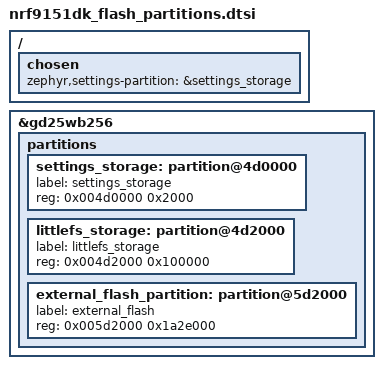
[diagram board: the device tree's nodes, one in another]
/*
 * Copyright (c) 2026 Nordic Semiconductor ASA
 *
 * SPDX-License-Identifier: LicenseRef-Nordic-5-Clause
 */

#include <samples/cellular/nrf91_updatable_bootloader_partitions.dtsi>

&gd25wb256 {
	status = "okay";

	#include <samples/cellular/nrf91_updatable_bootloader_external_partitions.dtsi>
};

#include "memfault_coredump_partition.dtsi"

/delete-node/ &external_flash_partition;

/ {
	chosen {
		zephyr,settings-partition = &settings_storage;
	};
};

&gd25wb256 {
	partitions {
		settings_storage: partition@4d0000 {
			label = "settings_storage";
			reg = <0x004d0000 0x2000>;
		};

		littlefs_storage: partition@4d2000 {
			label = "littlefs_storage";
			reg = <0x004d2000 0x100000>;
		};

		external_flash_partition: partition@5d2000 {
			label = "external_flash";
			reg = <0x005d2000 0x1a2e000>;
		};
	};
};
